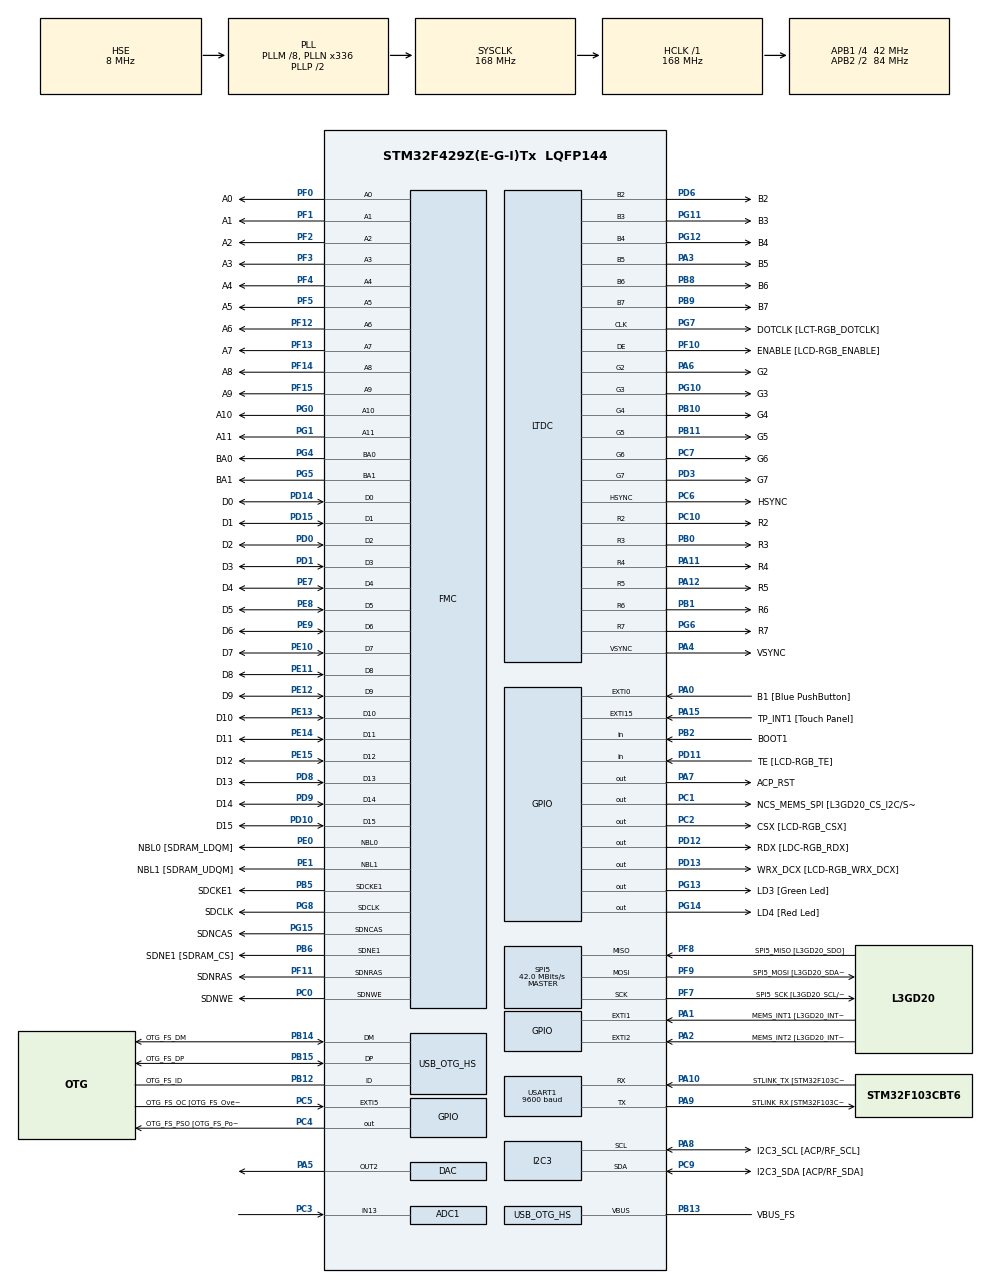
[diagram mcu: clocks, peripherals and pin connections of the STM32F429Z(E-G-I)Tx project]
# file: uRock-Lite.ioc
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ADC1.Channel-17\#ChannelRegularConversion=ADC_CHANNEL_13
ADC1.Channel-18\#ChannelRegularConversion=ADC_CHANNEL_13
ADC1.Channel-19\#ChannelRegularConversion=ADC_CHANNEL_13
ADC1.Channel-20\#ChannelRegularConversion=ADC_CHANNEL_13
ADC1.Channel-21\#ChannelRegularConversion=ADC_CHANNEL_13
ADC1.Channel-22\#ChannelRegularConversion=ADC_CHANNEL_13
ADC1.Channel-23\#ChannelRegularConversion=ADC_CHANNEL_13
ADC1.Channel-7\#ChannelRegularConversion=ADC_CHANNEL_13
ADC1.ClockPrescaler=ADC_CLOCKPRESCALER_PCLK_DIV8
ADC1.ContinuousConvMode=ENABLE
ADC1.DMAContinuousRequests=ENABLE
ADC1.DataAlign=ADC_DATAALIGN_RIGHT
ADC1.DiscontinuousConvMode=DISABLE
ADC1.EOCSelection=EOC_SINGLE_CONV
ADC1.EnableAnalogWatchDog=false
ADC1.ExternalTrigConvEdge=ADC_EXTERNALTRIGCONVEDGE_NONE
ADC1.InjNumberOfConversion=0
ADC1.NbrOfConversion=8
ADC1.NbrOfConversionFlag=1
ADC1.Rank-17\#ChannelRegularConversion=2
ADC1.Rank-18\#ChannelRegularConversion=3
ADC1.Rank-19\#ChannelRegularConversion=4
ADC1.Rank-20\#ChannelRegularConversion=5
ADC1.Rank-21\#ChannelRegularConversion=6
ADC1.Rank-22\#ChannelRegularConversion=7
ADC1.Rank-23\#ChannelRegularConversion=8
ADC1.Rank-7\#ChannelRegularConversion=1
ADC1.Resolution=ADC_RESOLUTION12b
ADC1.SamplingTime-17\#ChannelRegularConversion=ADC_SAMPLETIME_3CYCLES
ADC1.SamplingTime-18\#ChannelRegularConversion=ADC_SAMPLETIME_3CYCLES
ADC1.SamplingTime-19\#ChannelRegularConversion=ADC_SAMPLETIME_3CYCLES
ADC1.SamplingTime-20\#ChannelRegularConversion=ADC_SAMPLETIME_3CYCLES
ADC1.SamplingTime-21\#ChannelRegularConversion=ADC_SAMPLETIME_3CYCLES
ADC1.SamplingTime-22\#ChannelRegularConversion=ADC_SAMPLETIME_3CYCLES
ADC1.SamplingTime-23\#ChannelRegularConversion=ADC_SAMPLETIME_3CYCLES
ADC1.SamplingTime-7\#ChannelRegularConversion=ADC_SAMPLETIME_3CYCLES
ADC1.ScanConvMode=ENABLE
ADC1.master=1
DAC.DAC_Trigger2=DAC_TRIGGER_T6_TRGO
Dma.ADC1.2.Channel=DMA_CHANNEL_0
Dma.ADC1.2.Direction=DMA_PERIPH_TO_MEMORY
Dma.ADC1.2.FIFOMode=DMA_FIFOMODE_DISABLE
Dma.ADC1.2.Instance=DMA2_Stream4
Dma.ADC1.2.MemDataAlignment=DMA_MDATAALIGN_WORD
Dma.ADC1.2.MemInc=DMA_MINC_ENABLE
Dma.ADC1.2.Mode=DMA_CIRCULAR
Dma.ADC1.2.PeriphDataAlignment=DMA_PDATAALIGN_WORD
Dma.ADC1.2.PeriphInc=DMA_PINC_DISABLE
Dma.ADC1.2.Priority=DMA_PRIORITY_MEDIUM
Dma.DAC2.0.Channel=DMA_CHANNEL_7
Dma.DAC2.0.Direction=DMA_MEMORY_TO_PERIPH
Dma.DAC2.0.FIFOMode=DMA_FIFOMODE_DISABLE
Dma.DAC2.0.Instance=DMA1_Stream6
Dma.DAC2.0.MemDataAlignment=DMA_MDATAALIGN_WORD
Dma.DAC2.0.MemInc=DMA_MINC_ENABLE
Dma.DAC2.0.Mode=DMA_CIRCULAR
Dma.DAC2.0.PeriphDataAlignment=DMA_PDATAALIGN_WORD
Dma.DAC2.0.PeriphInc=DMA_PINC_DISABLE
Dma.DAC2.0.Priority=DMA_PRIORITY_VERY_HIGH
Dma.Request0=DAC2
Dma.Request1=TIM6_UP
Dma.Request2=ADC1
Dma.TIM6_UP.1.Channel=DMA_CHANNEL_7
Dma.TIM6_UP.1.Direction=DMA_PERIPH_TO_MEMORY
Dma.TIM6_UP.1.FIFOMode=DMA_FIFOMODE_DISABLE
Dma.TIM6_UP.1.Instance=DMA1_Stream1
Dma.TIM6_UP.1.MemDataAlignment=DMA_MDATAALIGN_HALFWORD
Dma.TIM6_UP.1.MemInc=DMA_MINC_ENABLE
Dma.TIM6_UP.1.Mode=DMA_NORMAL
Dma.TIM6_UP.1.PeriphDataAlignment=DMA_PDATAALIGN_HALFWORD
Dma.TIM6_UP.1.PeriphInc=DMA_PINC_DISABLE
Dma.TIM6_UP.1.Priority=DMA_PRIORITY_LOW
FREERTOS.Tasks01=SignalProcess,3,1024,SignalProcessTask
FREERTOS.configUSE_TIMERS=1
LTDC.Blue=128
LTDC.Blue_L0=128
LTDC.Blue_L1=255
LTDC.Green=128
LTDC.Green_L0=128
LTDC.Green_L1=255
LTDC.ImageHeight_L0=200
LTDC.ImageWidth_L0=200
LTDC.Layers=0
LTDC.Red=128
LTDC.Red_L0=128
LTDC.Red_L1=255
LTDC.WindowX1_L0=0
LTDC.WindowY1_L0=0
Mcu.Family=STM32F4
Mcu.Name=STM32F429Z(E-G-I)Tx
Mcu.Package=LQFP144
NVIC.DMA1_Stream1_IRQn=true\:5\:0\:false
NVIC.DMA1_Stream6_IRQn=true\:5\:0\:false
NVIC.DMA2_Stream4_IRQn=true\:5\:0\:false
NVIC.PriorityGroup=NVIC_PRIORITYGROUP_4
NVIC.USART1_IRQn=true\:5\:0\:false
PA0/WKUP.GPIO_Label=B1 [Blue PushButton]
PA0/WKUP.GPIO_ModeDefaultEXTI=GPIO_MODE_EVT_RISING
PA0/WKUP.GPIO_PuPd=GPIO_NOPULL
PA0/WKUP.Signal=GPXTI0
PA1.GPIO_Label=MEMS_INT1 [L3GD20_INT1]
PA1.GPIO_ModeDefaultEXTI=GPIO_MODE_EVT_RISING
PA1.GPIO_PuPd=GPIO_NOPULL
PA1.Signal=GPXTI1
PA10.GPIO_Label=STLINK_TX [STM32F103CBT6_PA2]
PA10.Mode=Asynchronous
PA10.Signal=USART1_RX
PA11.GPIO_Label=R4
PA11.GPIO_Mode=GPIO_MODE_AF_PP
PA11.GPIO_PuPd=GPIO_NOPULL
PA11.GPIO_Speed=GPIO_SPEED_LOW
PA11.Mode=RGB666
PA11.Signal=LTDC_R4
PA12.GPIO_Label=R5
PA12.GPIO_Mode=GPIO_MODE_AF_PP
PA12.GPIO_PuPd=GPIO_NOPULL
PA12.GPIO_Speed=GPIO_SPEED_LOW
PA12.Mode=RGB666
PA12.Signal=LTDC_R5
PA13.GPIO_Label=SWDIO
PA13.Mode=Serial-Wire
PA13.Signal=SYS_JTMS-SWDIO
PA14.GPIO_Label=SWCLK
PA14.Mode=Serial-Wire
PA14.Signal=SYS_JTCK-SWCLK
PA15.GPIO_Label=TP_INT1 [Touch Panel]
PA15.GPIO_ModeDefaultEXTI=GPIO_MODE_EVT_RISING
PA15.GPIO_PuPd=GPIO_NOPULL
PA15.Signal=GPXTI15
PA2.GPIO_Label=MEMS_INT2 [L3GD20_INT2]
PA2.GPIO_ModeDefaultEXTI=GPIO_MODE_EVT_RISING
PA2.GPIO_PuPd=GPIO_NOPULL
PA2.Signal=GPXTI2
PA3.GPIO_Label=B5
PA3.GPIO_Mode=GPIO_MODE_AF_PP
PA3.GPIO_PuPd=GPIO_NOPULL
PA3.GPIO_Speed=GPIO_SPEED_LOW
PA3.Mode=RGB666
PA3.Signal=LTDC_B5
PA4.GPIO_Label=VSYNC
PA4.GPIO_Mode=GPIO_MODE_AF_PP
PA4.GPIO_PuPd=GPIO_NOPULL
PA4.GPIO_Speed=GPIO_SPEED_LOW
PA4.Mode=RGB666
PA4.Signal=LTDC_VSYNC
PA5.Signal=COMP_DAC2_group
PA6.GPIO_Label=G2
PA6.GPIO_Mode=GPIO_MODE_AF_PP
PA6.GPIO_PuPd=GPIO_NOPULL
PA6.GPIO_Speed=GPIO_SPEED_LOW
PA6.Mode=RGB666
PA6.Signal=LTDC_G2
PA7.GPIO_Label=ACP_RST
PA7.GPIO_Mode=GPIO_MODE_OUTPUT_PP
PA7.GPIO_PuPd=GPIO_NOPULL
PA7.GPIO_Speed=GPIO_SPEED_LOW
PA7.Signal=GPIO_Output
PA8.GPIO_Label=I2C3_SCL [ACP/RF_SCL]
PA8.GPIO_Mode=GPIO_MODE_AF_OD
PA8.GPIO_PuPd=GPIO_NOPULL
PA8.GPIO_Speed=GPIO_SPEED_LOW
PA8.Mode=I2C
PA8.Signal=I2C3_SCL
PA9.GPIO_Label=STLINK_RX [STM32F103CBT6_PA3]
PA9.Mode=Asynchronous
PA9.Signal=USART1_TX
PB0.GPIO_Label=R3
PB0.GPIO_Mode=GPIO_MODE_AF_PP
PB0.GPIO_PuPd=GPIO_NOPULL
PB0.GPIO_Speed=GPIO_SPEED_LOW
PB0.Mode=RGB666
PB0.Signal=LTDC_R3
PB1.GPIO_Label=R6
PB1.GPIO_Mode=GPIO_MODE_AF_PP
PB1.GPIO_PuPd=GPIO_NOPULL
PB1.GPIO_Speed=GPIO_SPEED_LOW
PB1.Mode=RGB666
PB1.Signal=LTDC_R6
PB10.GPIO_Label=G4
PB10.GPIO_Mode=GPIO_MODE_AF_PP
PB10.GPIO_PuPd=GPIO_NOPULL
PB10.GPIO_Speed=GPIO_SPEED_LOW
PB10.Mode=RGB666
PB10.Signal=LTDC_G4
PB11.GPIO_Label=G5
PB11.GPIO_Mode=GPIO_MODE_AF_PP
PB11.GPIO_PuPd=GPIO_NOPULL
PB11.GPIO_Speed=GPIO_SPEED_LOW
PB11.Mode=RGB666
PB11.Signal=LTDC_G5
PB12.GPIO_Label=OTG_FS_ID
PB12.GPIO_Mode=GPIO_MODE_AF_PP
PB12.GPIO_PuPd=GPIO_NOPULL
PB12.GPIO_Speed=GPIO_SPEED_LOW
PB12.Mode=OTG/Dual-Role-Device-FS
PB12.Signal=USB_OTG_HS_ID
PB13.GPIO_Label=VBUS_FS
PB13.GPIO_Mode=GPIO_MODE_INPUT
PB13.GPIO_PuPd=GPIO_NOPULL
PB13.Mode=Activate_VBUS_FS
PB13.Signal=USB_OTG_HS_VBUS
PB14.GPIO_Label=OTG_FS_DM
PB14.GPIO_Mode=GPIO_MODE_AF_PP
PB14.GPIO_PuPd=GPIO_NOPULL
PB14.GPIO_Speed=GPIO_SPEED_LOW
PB14.Mode=OTG/Dual-Role-Device-FS
PB14.Signal=USB_OTG_HS_DM
PB15.GPIO_Label=OTG_FS_DP
PB15.GPIO_Mode=GPIO_MODE_AF_PP
PB15.GPIO_PuPd=GPIO_NOPULL
PB15.GPIO_Speed=GPIO_SPEED_LOW
PB15.Mode=OTG/Dual-Role-Device-FS
PB15.Signal=USB_OTG_HS_DP
PB2/BOOT1.GPIO_Label=BOOT1
PB2/BOOT1.GPIO_Mode=GPIO_MODE_INPUT
PB2/BOOT1.GPIO_PuPd=GPIO_NOPULL
PB2/BOOT1.Signal=GPIO_Input
PB5.GPIO_Label=SDCKE1
PB5.GPIO_Mode=GPIO_MODE_AF_PP
PB5.GPIO_PuPd=GPIO_NOPULL
PB5.GPIO_Speed=GPIO_SPEED_HIGH
PB5.Mode=SdramChipSelect2_1
PB5.Signal=FMC_SDCKE1
PB6.GPIO_Label=SDNE1 [SDRAM_CS]
PB6.GPIO_Mode=GPIO_MODE_AF_PP
PB6.GPIO_PuPd=GPIO_NOPULL
PB6.GPIO_Speed=GPIO_SPEED_HIGH
PB6.Mode=SdramChipSelect2_1
PB6.Signal=FMC_SDNE1
PB8.GPIO_Label=B6
PB8.GPIO_Mode=GPIO_MODE_AF_PP
PB8.GPIO_PuPd=GPIO_NOPULL
PB8.GPIO_Speed=GPIO_SPEED_LOW
PB8.Mode=RGB666
PB8.Signal=LTDC_B6
PB9.GPIO_Label=B7
PB9.GPIO_Mode=GPIO_MODE_AF_PP
PB9.GPIO_PuPd=GPIO_NOPULL
PB9.GPIO_Speed=GPIO_SPEED_LOW
PB9.Mode=RGB666
PB9.Signal=LTDC_B7
PC0.GPIO_Label=SDNWE
PC0.GPIO_Mode=GPIO_MODE_AF_PP
PC0.GPIO_PuPd=GPIO_NOPULL
PC0.GPIO_Speed=GPIO_SPEED_HIGH
PC0.Signal=FMC_SDNWE
PC1.GPIO_Label=NCS_MEMS_SPI [L3GD20_CS_I2C/SPI]
PC1.GPIO_Mode=GPIO_MODE_OUTPUT_PP
PC1.GPIO_PuPd=GPIO_NOPULL
PC1.GPIO_Speed=GPIO_SPEED_LOW
PC1.Signal=GPIO_Output
PC10.GPIO_Label=R2
PC10.GPIO_Mode=GPIO_MODE_AF_PP
PC10.GPIO_PuPd=GPIO_NOPULL
PC10.GPIO_Speed=GPIO_SPEED_LOW
PC10.Mode=RGB666
PC10.Signal=LTDC_R2
PC14/OSC32_IN.GPIO_Label=PC14-OSC32_IN
PC14/OSC32_IN.Signal=RCC_OSC32_IN
PC15/OSC32_OUT.GPIO_Label=PC15-OSC32_OUT
PC15/OSC32_OUT.Signal=RCC_OSC32_OUT
PC2.GPIO_Label=CSX [LCD-RGB_CSX]
PC2.GPIO_Mode=GPIO_MODE_OUTPUT_PP
PC2.GPIO_PuPd=GPIO_NOPULL
PC2.GPIO_Speed=GPIO_SPEED_LOW
PC2.Signal=GPIO_Output
PC3.Signal=ADCx_IN13
PC4.GPIO_Label=OTG_FS_PSO [OTG_FS_PowerSwitchOn]
PC4.GPIO_Mode=GPIO_MODE_OUTPUT_PP
PC4.GPIO_PuPd=GPIO_NOPULL
PC4.GPIO_Speed=GPIO_SPEED_LOW
PC4.Signal=GPIO_Output
PC5.GPIO_Label=OTG_FS_OC [OTG_FS_OverCurrent]
PC5.GPIO_ModeDefaultEXTI=GPIO_MODE_EVT_RISING
PC5.Signal=GPXTI5
PC6.GPIO_Label=HSYNC
PC6.GPIO_Mode=GPIO_MODE_AF_PP
PC6.GPIO_PuPd=GPIO_NOPULL
PC6.GPIO_Speed=GPIO_SPEED_LOW
PC6.Mode=RGB666
PC6.Signal=LTDC_HSYNC
PC7.GPIO_Label=G6
PC7.GPIO_Mode=GPIO_MODE_AF_PP
PC7.GPIO_PuPd=GPIO_NOPULL
PC7.GPIO_Speed=GPIO_SPEED_LOW
PC7.Mode=RGB666
PC7.Signal=LTDC_G6
PC9.GPIO_Label=I2C3_SDA [ACP/RF_SDA]
PC9.GPIO_Mode=GPIO_MODE_AF_OD
PC9.GPIO_PuPd=GPIO_NOPULL
PC9.GPIO_Speed=GPIO_SPEED_LOW
PC9.Mode=I2C
PC9.Signal=I2C3_SDA
PD0.GPIO_Label=D2
PD0.GPIO_Mode=GPIO_MODE_AF_PP
PD0.GPIO_PuPd=GPIO_NOPULL
PD0.GPIO_Speed=GPIO_SPEED_HIGH
PD0.Signal=FMC_D2_DA2
PD1.GPIO_Label=D3
PD1.GPIO_Mode=GPIO_MODE_AF_PP
PD1.GPIO_PuPd=GPIO_NOPULL
PD1.GPIO_Speed=GPIO_SPEED_HIGH
PD1.Signal=FMC_D3_DA3
PD10.GPIO_Label=D15
PD10.GPIO_Mode=GPIO_MODE_AF_PP
PD10.GPIO_PuPd=GPIO_NOPULL
PD10.GPIO_Speed=GPIO_SPEED_HIGH
PD10.Signal=FMC_D15_DA15
PD11.GPIO_Label=TE [LCD-RGB_TE]
PD11.GPIO_Mode=GPIO_MODE_INPUT
PD11.GPIO_PuPd=GPIO_NOPULL
PD11.Signal=GPIO_Input
PD12.GPIO_Label=RDX [LDC-RGB_RDX]
PD12.GPIO_Mode=GPIO_MODE_OUTPUT_PP
PD12.GPIO_PuPd=GPIO_NOPULL
PD12.GPIO_Speed=GPIO_SPEED_LOW
PD12.Signal=GPIO_Output
PD13.GPIO_Label=WRX_DCX [LCD-RGB_WRX_DCX]
PD13.GPIO_Mode=GPIO_MODE_OUTPUT_PP
PD13.GPIO_PuPd=GPIO_NOPULL
PD13.GPIO_Speed=GPIO_SPEED_LOW
PD13.Signal=GPIO_Output
PD14.GPIO_Label=D0
PD14.GPIO_Mode=GPIO_MODE_AF_PP
PD14.GPIO_PuPd=GPIO_NOPULL
PD14.GPIO_Speed=GPIO_SPEED_HIGH
PD14.Signal=FMC_D0_DA0
PD15.GPIO_Label=D1
PD15.GPIO_Mode=GPIO_MODE_AF_PP
PD15.GPIO_PuPd=GPIO_NOPULL
PD15.GPIO_Speed=GPIO_SPEED_HIGH
PD15.Signal=FMC_D1_DA1
PD3.GPIO_Label=G7
PD3.GPIO_Mode=GPIO_MODE_AF_PP
PD3.GPIO_PuPd=GPIO_NOPULL
PD3.GPIO_Speed=GPIO_SPEED_LOW
PD3.Mode=RGB666
PD3.Signal=LTDC_G7
PD6.GPIO_Label=B2
PD6.GPIO_Mode=GPIO_MODE_AF_PP
PD6.GPIO_PuPd=GPIO_NOPULL
PD6.GPIO_Speed=GPIO_SPEED_LOW
PD6.Mode=RGB666
PD6.Signal=LTDC_B2
PD8.GPIO_Label=D13
PD8.GPIO_Mode=GPIO_MODE_AF_PP
PD8.GPIO_PuPd=GPIO_NOPULL
PD8.GPIO_Speed=GPIO_SPEED_HIGH
PD8.Signal=FMC_D13_DA13
PD9.GPIO_Label=D14
PD9.GPIO_Mode=GPIO_MODE_AF_PP
PD9.GPIO_PuPd=GPIO_NOPULL
PD9.GPIO_Speed=GPIO_SPEED_HIGH
PD9.Signal=FMC_D14_DA14
PE0.GPIO_Label=NBL0 [SDRAM_LDQM]
PE0.GPIO_Mode=GPIO_MODE_AF_PP
PE0.GPIO_PuPd=GPIO_NOPULL
PE0.GPIO_Speed=GPIO_SPEED_HIGH
PE0.Signal=FMC_NBL0
PE1.GPIO_Label=NBL1 [SDRAM_UDQM]
PE1.GPIO_Mode=GPIO_MODE_AF_PP
PE1.GPIO_PuPd=GPIO_NOPULL
PE1.GPIO_Speed=GPIO_SPEED_HIGH
PE1.Signal=FMC_NBL1
PE10.GPIO_Label=D7
PE10.GPIO_Mode=GPIO_MODE_AF_PP
PE10.GPIO_PuPd=GPIO_NOPULL
PE10.GPIO_Speed=GPIO_SPEED_HIGH
PE10.Signal=FMC_D7_DA7
PE11.GPIO_Label=D8
PE11.GPIO_Mode=GPIO_MODE_AF_PP
PE11.GPIO_PuPd=GPIO_NOPULL
PE11.GPIO_Speed=GPIO_SPEED_HIGH
PE11.Signal=FMC_D8_DA8
PE12.GPIO_Label=D9
PE12.GPIO_Mode=GPIO_MODE_AF_PP
PE12.GPIO_PuPd=GPIO_NOPULL
PE12.GPIO_Speed=GPIO_SPEED_HIGH
PE12.Signal=FMC_D9_DA9
PE13.GPIO_Label=D10
PE13.GPIO_Mode=GPIO_MODE_AF_PP
PE13.GPIO_PuPd=GPIO_NOPULL
PE13.GPIO_Speed=GPIO_SPEED_HIGH
PE13.Signal=FMC_D10_DA10
PE14.GPIO_Label=D11
PE14.GPIO_Mode=GPIO_MODE_AF_PP
PE14.GPIO_PuPd=GPIO_NOPULL
PE14.GPIO_Speed=GPIO_SPEED_HIGH
PE14.Signal=FMC_D11_DA11
PE15.GPIO_Label=D12
PE15.GPIO_Mode=GPIO_MODE_AF_PP
PE15.GPIO_PuPd=GPIO_NOPULL
PE15.GPIO_Speed=GPIO_SPEED_HIGH
PE15.Signal=FMC_D12_DA12
PE7.GPIO_Label=D4
PE7.GPIO_Mode=GPIO_MODE_AF_PP
PE7.GPIO_PuPd=GPIO_NOPULL
PE7.GPIO_Speed=GPIO_SPEED_HIGH
PE7.Signal=FMC_D4_DA4
PE8.GPIO_Label=D5
PE8.GPIO_Mode=GPIO_MODE_AF_PP
PE8.GPIO_PuPd=GPIO_NOPULL
PE8.GPIO_Speed=GPIO_SPEED_HIGH
PE8.Signal=FMC_D5_DA5
PE9.GPIO_Label=D6
PE9.GPIO_Mode=GPIO_MODE_AF_PP
PE9.GPIO_PuPd=GPIO_NOPULL
PE9.GPIO_Speed=GPIO_SPEED_HIGH
PE9.Signal=FMC_D6_DA6
PF0.GPIO_Label=A0
PF0.GPIO_Mode=GPIO_MODE_AF_PP
PF0.GPIO_PuPd=GPIO_NOPULL
PF0.GPIO_Speed=GPIO_SPEED_HIGH
PF0.Signal=FMC_A0
PF1.GPIO_Label=A1
PF1.GPIO_Mode=GPIO_MODE_AF_PP
PF1.GPIO_PuPd=GPIO_NOPULL
PF1.GPIO_Speed=GPIO_SPEED_HIGH
PF1.Signal=FMC_A1
PF10.GPIO_Label=ENABLE [LCD-RGB_ENABLE]
PF10.GPIO_Mode=GPIO_MODE_AF_PP
PF10.GPIO_PuPd=GPIO_NOPULL
PF10.GPIO_Speed=GPIO_SPEED_LOW
PF10.Mode=RGB666
PF10.Signal=LTDC_DE
PF11.GPIO_Label=SDNRAS
PF11.GPIO_Mode=GPIO_MODE_AF_PP
PF11.GPIO_PuPd=GPIO_NOPULL
PF11.GPIO_Speed=GPIO_SPEED_HIGH
PF11.Signal=FMC_SDNRAS
PF12.GPIO_Label=A6
PF12.GPIO_Mode=GPIO_MODE_AF_PP
PF12.GPIO_PuPd=GPIO_NOPULL
PF12.GPIO_Speed=GPIO_SPEED_HIGH
PF12.Signal=FMC_A6
PF13.GPIO_Label=A7
PF13.GPIO_Mode=GPIO_MODE_AF_PP
PF13.GPIO_PuPd=GPIO_NOPULL
PF13.GPIO_Speed=GPIO_SPEED_HIGH
PF13.Signal=FMC_A7
PF14.GPIO_Label=A8
PF14.GPIO_Mode=GPIO_MODE_AF_PP
PF14.GPIO_PuPd=GPIO_NOPULL
PF14.GPIO_Speed=GPIO_SPEED_HIGH
PF14.Signal=FMC_A8
PF15.GPIO_Label=A9
PF15.GPIO_Mode=GPIO_MODE_AF_PP
PF15.GPIO_PuPd=GPIO_NOPULL
PF15.GPIO_Speed=GPIO_SPEED_HIGH
PF15.Signal=FMC_A9
PF2.GPIO_Label=A2
PF2.GPIO_Mode=GPIO_MODE_AF_PP
PF2.GPIO_PuPd=GPIO_NOPULL
PF2.GPIO_Speed=GPIO_SPEED_HIGH
PF2.Signal=FMC_A2
PF3.GPIO_Label=A3
PF3.GPIO_Mode=GPIO_MODE_AF_PP
PF3.GPIO_PuPd=GPIO_NOPULL
PF3.GPIO_Speed=GPIO_SPEED_HIGH
PF3.Signal=FMC_A3
PF4.GPIO_Label=A4
PF4.GPIO_Mode=GPIO_MODE_AF_PP
PF4.GPIO_PuPd=GPIO_NOPULL
PF4.GPIO_Speed=GPIO_SPEED_HIGH
PF4.Signal=FMC_A4
PF5.GPIO_Label=A5
PF5.GPIO_Mode=GPIO_MODE_AF_PP
PF5.GPIO_PuPd=GPIO_NOPULL
PF5.GPIO_Speed=GPIO_SPEED_HIGH
PF5.Signal=FMC_A5
PF7.GPIO_Label=SPI5_SCK [L3GD20_SCL/SPC]
PF7.GPIO_Mode=GPIO_MODE_AF_PP
PF7.GPIO_PuPd=GPIO_NOPULL
PF7.GPIO_Speed=GPIO_SPEED_LOW
PF7.Mode=Full_Duplex_Master
PF7.Signal=SPI5_SCK
PF8.GPIO_Label=SPI5_MISO [L3GD20_SDO]
PF8.GPIO_Mode=GPIO_MODE_AF_PP
PF8.GPIO_PuPd=GPIO_NOPULL
PF8.GPIO_Speed=GPIO_SPEED_LOW
PF8.Mode=Full_Duplex_Master
PF8.Signal=SPI5_MISO
PF9.GPIO_Label=SPI5_MOSI [L3GD20_SDA/SDI/SDO]
PF9.GPIO_Mode=GPIO_MODE_AF_PP
PF9.GPIO_PuPd=GPIO_NOPULL
PF9.GPIO_Speed=GPIO_SPEED_LOW
PF9.Mode=Full_Duplex_Master
PF9.Signal=SPI5_MOSI
PG0.GPIO_Label=A10
PG0.GPIO_Mode=GPIO_MODE_AF_PP
PG0.GPIO_PuPd=GPIO_NOPULL
PG0.GPIO_Speed=GPIO_SPEED_HIGH
PG0.Signal=FMC_A10
PG1.GPIO_Label=A11
PG1.GPIO_Mode=GPIO_MODE_AF_PP
PG1.GPIO_PuPd=GPIO_NOPULL
PG1.GPIO_Speed=GPIO_SPEED_HIGH
PG1.Signal=FMC_A11
PG10.GPIO_Label=G3
PG10.GPIO_Mode=GPIO_MODE_AF_PP
PG10.GPIO_PuPd=GPIO_NOPULL
PG10.GPIO_Speed=GPIO_SPEED_LOW
PG10.Mode=RGB666
PG10.Signal=LTDC_G3
PG11.GPIO_Label=B3
PG11.GPIO_Mode=GPIO_MODE_AF_PP
PG11.GPIO_PuPd=GPIO_NOPULL
PG11.GPIO_Speed=GPIO_SPEED_LOW
PG11.Mode=RGB666
PG11.Signal=LTDC_B3
PG12.GPIO_Label=B4
PG12.GPIO_Mode=GPIO_MODE_AF_PP
PG12.GPIO_PuPd=GPIO_NOPULL
PG12.GPIO_Speed=GPIO_SPEED_LOW
PG12.Mode=RGB666
PG12.Signal=LTDC_B4
PG13.GPIO_Label=LD3 [Green Led]
PG13.GPIO_Mode=GPIO_MODE_OUTPUT_PP
PG13.GPIO_PuPd=GPIO_NOPULL
PG13.GPIO_Speed=GPIO_SPEED_LOW
PG13.Signal=GPIO_Output
PG14.GPIO_Label=LD4 [Red Led]
PG14.GPIO_Mode=GPIO_MODE_OUTPUT_PP
PG14.GPIO_PuPd=GPIO_NOPULL
PG14.GPIO_Speed=GPIO_SPEED_LOW
PG14.Signal=GPIO_Output
PG15.GPIO_Label=SDNCAS
PG15.GPIO_Mode=GPIO_MODE_AF_PP
PG15.GPIO_PuPd=GPIO_NOPULL
PG15.GPIO_Speed=GPIO_SPEED_HIGH
PG15.Signal=FMC_SDNCAS
PG4.GPIO_Label=BA0
PG4.GPIO_Mode=GPIO_MODE_AF_PP
PG4.GPIO_PuPd=GPIO_NOPULL
PG4.GPIO_Speed=GPIO_SPEED_HIGH
PG4.Signal=FMC_A14_BA0
PG5.GPIO_Label=BA1
PG5.GPIO_Mode=GPIO_MODE_AF_PP
PG5.GPIO_PuPd=GPIO_NOPULL
PG5.GPIO_Speed=GPIO_SPEED_HIGH
PG5.Signal=FMC_A15_BA1
PG6.GPIO_Label=R7
PG6.GPIO_Mode=GPIO_MODE_AF_PP
PG6.GPIO_PuPd=GPIO_NOPULL
PG6.GPIO_Speed=GPIO_SPEED_LOW
PG6.Mode=RGB666
PG6.Signal=LTDC_R7
PG7.GPIO_Label=DOTCLK [LCT-RGB_DOTCLK]
PG7.GPIO_Mode=GPIO_MODE_AF_PP
PG7.GPIO_PuPd=GPIO_NOPULL
PG7.GPIO_Speed=GPIO_SPEED_LOW
PG7.Mode=RGB666
PG7.Signal=LTDC_CLK
PG8.GPIO_Label=SDCLK
PG8.GPIO_Mode=GPIO_MODE_AF_PP
PG8.GPIO_PuPd=GPIO_NOPULL
PG8.GPIO_Speed=GPIO_SPEED_HIGH
PG8.Signal=FMC_SDCLK
PH0/OSC_IN.GPIO_Label=PH0-OSC_IN
PH0/OSC_IN.Mode=HSE-External-Oscillator
PH0/OSC_IN.Signal=RCC_OSC_IN
PH1/OSC_OUT.GPIO_Label=PH1-OSC_OUT
PH1/OSC_OUT.Mode=HSE-External-Oscillator
PH1/OSC_OUT.Signal=RCC_OSC_OUT
ProjectManager.TargetToolchain=SW4STM32
RCC.48MHZClocksFreq_Value=48000000
RCC.AHBFreq_Value=168000000
RCC.APB1CLKDivider=RCC_HCLK_DIV4
RCC.APB1Freq_Value=42000000
RCC.APB1TimFreq_Value=84000000
RCC.APB2CLKDivider=RCC_HCLK_DIV2
RCC.APB2Freq_Value=84000000
RCC.APB2TimFreq_Value=168000000
RCC.CortexFreq_Value=168000000
RCC.HCLKFreq_Value=168000000
RCC.HSE_VALUE=8000000
RCC.HSI_VALUE=16000000
RCC.LSE_VALUE=32768
RCC.PLLM=8
RCC.PLLN=336
RCC.PLLQ=7
RCC.PLLSAIN=260
RCC.SYSCLKFreq_VALUE=168000000
RCC.SYSCLKSource=RCC_SYSCLKSOURCE_PLLCLK
RCC.VCOOutputFreq_Value=336000000
SH.ADCx_IN13.0=ADC1_IN13,IN13
SH.COMP_DAC2_group.0=DAC_OUT2,DAC_OUT2
SH.FMC_A0.0=FMC_A0,12b-sda1
SH.FMC_A1.0=FMC_A1,12b-sda1
SH.FMC_A10.0=FMC_A10,12b-sda1
SH.FMC_A11.0=FMC_A11,12b-sda1
SH.FMC_A14_BA0.0=FMC_BA0,FourSdramBanks1
SH.FMC_A15_BA1.0=FMC_BA1,FourSdramBanks1
SH.FMC_A2.0=FMC_A2,12b-sda1
SH.FMC_A3.0=FMC_A3,12b-sda1
SH.FMC_A4.0=FMC_A4,12b-sda1
SH.FMC_A5.0=FMC_A5,12b-sda1
SH.FMC_A6.0=FMC_A6,12b-sda1
SH.FMC_A7.0=FMC_A7,12b-sda1
SH.FMC_A8.0=FMC_A8,12b-sda1
SH.FMC_A9.0=FMC_A9,12b-sda1
SH.FMC_D0_DA0.0=FMC_D0,sd-16b-d1
SH.FMC_D10_DA10.0=FMC_D10,sd-16b-d1
SH.FMC_D11_DA11.0=FMC_D11,sd-16b-d1
SH.FMC_D12_DA12.0=FMC_D12,sd-16b-d1
SH.FMC_D13_DA13.0=FMC_D13,sd-16b-d1
SH.FMC_D14_DA14.0=FMC_D14,sd-16b-d1
SH.FMC_D15_DA15.0=FMC_D15,sd-16b-d1
SH.FMC_D1_DA1.0=FMC_D1,sd-16b-d1
SH.FMC_D2_DA2.0=FMC_D2,sd-16b-d1
SH.FMC_D3_DA3.0=FMC_D3,sd-16b-d1
SH.FMC_D4_DA4.0=FMC_D4,sd-16b-d1
SH.FMC_D5_DA5.0=FMC_D5,sd-16b-d1
SH.FMC_D6_DA6.0=FMC_D6,sd-16b-d1
SH.FMC_D7_DA7.0=FMC_D7,sd-16b-d1
SH.FMC_D8_DA8.0=FMC_D8,sd-16b-d1
SH.FMC_D9_DA9.0=FMC_D9,sd-16b-d1
SH.FMC_NBL0.0=FMC_NBL0,Sd2ByteEnable1
SH.FMC_NBL1.0=FMC_NBL1,Sd2ByteEnable1
SH.FMC_SDCLK.0=FMC_SDCLK,12b-sda1
SH.FMC_SDNCAS.0=FMC_SDNCAS,12b-sda1
SH.FMC_SDNRAS.0=FMC_SDNRAS,12b-sda1
SH.FMC_SDNWE.0=FMC_SDNWE,12b-sda1
SPI5.CalculateBaudRate=42.0 MBits/s
SPI5.Mode=SPI_MODE_MASTER
TIM6.Period=0x0ED
TIM6.TIM_MasterOutputTrigger=TIM_TRGO_UPDATE
USART1.BaudRate=9600
VP_FREERTOS_VS_ENABLE.Mode=Enabled
VP_TIM6_VS_ClockSourceINT.Mode=Enable_Timer
board=STM32F429I-DISC1

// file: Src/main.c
/**
  ******************************************************************************
  * File Name          : main.c
  * Description        : Main program body
  ******************************************************************************
  *
  * COPYRIGHT(c) 2016 STMicroelectronics
  *
  * Redistribution and use in source and binary forms, with or without modification,
  * are permitted provided that the following conditions are met:
  *   1. Redistributions of source code must retain the above copyright notice,
  *      this list of conditions and the following disclaimer.
  *   2. Redistributions in binary form must reproduce the above copyright notice,
  *      this list of conditions and the following disclaimer in the documentation
  *      and/or other materials provided with the distribution.
  *   3. Neither the name of STMicroelectronics nor the names of its contributors
  *      may be used to endorse or promote products derived from this software
  *      without specific prior written permission.
  *
  * THIS SOFTWARE IS PROVIDED BY THE COPYRIGHT HOLDERS AND CONTRIBUTORS "AS IS"
  * AND ANY EXPRESS OR IMPLIED WARRANTIES, INCLUDING, BUT NOT LIMITED TO, THE
  * IMPLIED WARRANTIES OF MERCHANTABILITY AND FITNESS FOR A PARTICULAR PURPOSE ARE
  * DISCLAIMED. IN NO EVENT SHALL THE COPYRIGHT HOLDER OR CONTRIBUTORS BE LIABLE
  * FOR ANY DIRECT, INDIRECT, INCIDENTAL, SPECIAL, EXEMPLARY, OR CONSEQUENTIAL
  * DAMAGES (INCLUDING, BUT NOT LIMITED TO, PROCUREMENT OF SUBSTITUTE GOODS OR
  * SERVICES; LOSS OF USE, DATA, OR PROFITS; OR BUSINESS INTERRUPTION) HOWEVER
  * CAUSED AND ON ANY THEORY OF LIABILITY, WHETHER IN CONTRACT, STRICT LIABILITY,
  * OR TORT (INCLUDING NEGLIGENCE OR OTHERWISE) ARISING IN ANY WAY OUT OF THE USE
  * OF THIS SOFTWARE, EVEN IF ADVISED OF THE POSSIBILITY OF SUCH DAMAGE.
  *
  ******************************************************************************
  */
#include "stm32f4xx_hal.h"
#include "cmsis_os.h"

/* USER CODE BEGIN Includes */
#include "param.h"
#include "effect.h"
#include "dsp.h"
#include "bluetooth_handler.h"
/* USER CODE END Includes */

ADC_HandleTypeDef hadc1;
DMA_HandleTypeDef hdma_adc1;

DAC_HandleTypeDef hdac;
DMA_HandleTypeDef hdma_dac2;

I2C_HandleTypeDef hi2c3;

LTDC_HandleTypeDef hltdc;

SPI_HandleTypeDef hspi5;

TIM_HandleTypeDef htim6;
DMA_HandleTypeDef hdma_tim6_up;

UART_HandleTypeDef huart1;

SDRAM_HandleTypeDef hsdram1;
osThreadId SignalProcessHandle;

/* USER CODE BEGIN PV */
/* Private variables ---------------------------------------------------------*/

/* USER CODE END PV */

void SystemClock_Config(void);
static void MX_GPIO_Init(void);
static void MX_DMA_Init(void);
static void MX_ADC1_Init(void);
static void MX_DAC_Init(void);
static void MX_FMC_Init(void);
static void MX_I2C3_Init(void);
static void MX_LTDC_Init(void);
static void MX_SPI5_Init(void);
static void MX_TIM6_Init(void);
static void MX_USART1_UART_Init(void);
static void MX_USB_OTG_HS_USB_Init(void);
void SignalProcessTask(void const * argument);

/* USER CODE BEGIN PFP */
/* Private function prototypes -----------------------------------------------*/

/* USER CODE END PFP */

int main(void)
{

  /* MCU Configuration----------------------------------------------------------*/

  /* Reset of all peripherals, Initializes the Flash interface and the Systick. */
  HAL_Init();

  /* Configure the system clock */
  SystemClock_Config();

  /* Initialize all configured peripherals */
  MX_GPIO_Init();
  MX_DMA_Init();
  MX_ADC1_Init();
  MX_DAC_Init();
  MX_FMC_Init();
  MX_I2C3_Init();
  MX_LTDC_Init();
  MX_SPI5_Init();
  MX_TIM6_Init();
  MX_USART1_UART_Init();
  MX_USB_OTG_HS_USB_Init();

  /* Create the thread(s) */
  /* definition and creation of SignalProcess */
  osThreadDef(SignalProcess, SignalProcessTask, osPriorityRealtime, 0, 1024);
  SignalProcessHandle = osThreadCreate(osThread(SignalProcess), NULL);

  /* Start scheduler */
  osKernelStart();

  /* We should never get here as control is now taken by the scheduler */

  /* Infinite loop */
  while (1)
  {

  }

}

/** System Clock Configuration
*/
void SystemClock_Config(void)
{

  RCC_OscInitTypeDef RCC_OscInitStruct;
  RCC_ClkInitTypeDef RCC_ClkInitStruct;
  RCC_PeriphCLKInitTypeDef PeriphClkInitStruct;

  __PWR_CLK_ENABLE();

  __HAL_PWR_VOLTAGESCALING_CONFIG(PWR_REGULATOR_VOLTAGE_SCALE1);

  RCC_OscInitStruct.OscillatorType = RCC_OSCILLATORTYPE_HSE;
  RCC_OscInitStruct.HSEState = RCC_HSE_ON;
  RCC_OscInitStruct.PLL.PLLState = RCC_PLL_ON;
  RCC_OscInitStruct.PLL.PLLSource = RCC_PLLSOURCE_HSE;
  RCC_OscInitStruct.PLL.PLLM = 8;
  RCC_OscInitStruct.PLL.PLLN = 336;
  RCC_OscInitStruct.PLL.PLLP = RCC_PLLP_DIV2;
  RCC_OscInitStruct.PLL.PLLQ = 7;
  HAL_RCC_OscConfig(&RCC_OscInitStruct);

  RCC_ClkInitStruct.ClockType = RCC_CLOCKTYPE_SYSCLK|RCC_CLOCKTYPE_PCLK1
                              |RCC_CLOCKTYPE_PCLK2;
  RCC_ClkInitStruct.SYSCLKSource = RCC_SYSCLKSOURCE_PLLCLK;
  RCC_ClkInitStruct.AHBCLKDivider = RCC_SYSCLK_DIV1;
  RCC_ClkInitStruct.APB1CLKDivider = RCC_HCLK_DIV4;
  RCC_ClkInitStruct.APB2CLKDivider = RCC_HCLK_DIV2;
  HAL_RCC_ClockConfig(&RCC_ClkInitStruct, FLASH_LATENCY_5);

  PeriphClkInitStruct.PeriphClockSelection = RCC_PERIPHCLK_LTDC;
  PeriphClkInitStruct.PLLSAI.PLLSAIN = 260;
  PeriphClkInitStruct.PLLSAI.PLLSAIR = 2;
  PeriphClkInitStruct.PLLSAIDivR = RCC_PLLSAIDIVR_2;
  HAL_RCCEx_PeriphCLKConfig(&PeriphClkInitStruct);

  HAL_SYSTICK_Config(HAL_RCC_GetHCLKFreq()/1000);

  HAL_SYSTICK_CLKSourceConfig(SYSTICK_CLKSOURCE_HCLK);

  /* SysTick_IRQn interrupt configuration */
  HAL_NVIC_SetPriority(SysTick_IRQn, 15, 0);
}

/* ADC1 init function */
void MX_ADC1_Init(void)
{

  ADC_ChannelConfTypeDef sConfig;

    /**Configure the global features of the ADC (Clock, Resolution, Data Alignment and number of conversion)
    */
  hadc1.Instance = ADC1;
  hadc1.Init.ClockPrescaler = ADC_CLOCKPRESCALER_PCLK_DIV8;
  hadc1.Init.Resolution = ADC_RESOLUTION12b;
  hadc1.Init.ScanConvMode = ENABLE;
  hadc1.Init.ContinuousConvMode = ENABLE;
  hadc1.Init.DiscontinuousConvMode = DISABLE;
  hadc1.Init.ExternalTrigConvEdge = ADC_EXTERNALTRIGCONVEDGE_NONE;
  hadc1.Init.DataAlign = ADC_DATAALIGN_RIGHT;
  hadc1.Init.NbrOfConversion = 8;
  hadc1.Init.DMAContinuousRequests = ENABLE;
  hadc1.Init.EOCSelection = EOC_SINGLE_CONV;
  HAL_ADC_Init(&hadc1);

    /**Configure for the selected ADC regular channel its corresponding rank in the sequencer and its sample time.
    */
  sConfig.Channel = ADC_CHANNEL_13;
  sConfig.Rank = 1;
  sConfig.SamplingTime = ADC_SAMPLETIME_3CYCLES;
  HAL_ADC_ConfigChannel(&hadc1, &sConfig);

    /**Configure for the selected ADC regular channel its corresponding rank in the sequencer and its sample time.
    */
  sConfig.Rank = 2;
  HAL_ADC_ConfigChannel(&hadc1, &sConfig);

    /**Configure for the selected ADC regular channel its corresponding rank in the sequencer and its sample time.
    */
  sConfig.Rank = 3;
  HAL_ADC_ConfigChannel(&hadc1, &sConfig);

    /**Configure for the selected ADC regular channel its corresponding rank in the sequencer and its sample time.
    */
  sConfig.Rank = 4;
  HAL_ADC_ConfigChannel(&hadc1, &sConfig);

    /**Configure for the selected ADC regular channel its corresponding rank in the sequencer and its sample time.
    */
  sConfig.Rank = 5;
  HAL_ADC_ConfigChannel(&hadc1, &sConfig);

    /**Configure for the selected ADC regular channel its corresponding rank in the sequencer and its sample time.
    */
  sConfig.Rank = 6;
  HAL_ADC_ConfigChannel(&hadc1, &sConfig);

    /**Configure for the selected ADC regular channel its corresponding rank in the sequencer and its sample time.
    */
  sConfig.Rank = 7;
  HAL_ADC_ConfigChannel(&hadc1, &sConfig);

    /**Configure for the selected ADC regular channel its corresponding rank in the sequencer and its sample time.
    */
  sConfig.Rank = 8;
  HAL_ADC_ConfigChannel(&hadc1, &sConfig);

}

/* DAC init function */
void MX_DAC_Init(void)
{

  DAC_ChannelConfTypeDef sConfig;

    /**DAC Initialization
    */
  hdac.Instance = DAC;
  HAL_DAC_Init(&hdac);

    /**DAC channel OUT2 config
    */
  sConfig.DAC_Trigger = DAC_TRIGGER_T6_TRGO;
  sConfig.DAC_OutputBuffer = DAC_OUTPUTBUFFER_ENABLE;
  HAL_DAC_ConfigChannel(&hdac, &sConfig, DAC_CHANNEL_2);

}

/* I2C3 init function */
void MX_I2C3_Init(void)
{

  hi2c3.Instance = I2C3;
  hi2c3.Init.ClockSpeed = 100000;
  hi2c3.Init.DutyCycle = I2C_DUTYCYCLE_2;
  hi2c3.Init.OwnAddress1 = 0;
  hi2c3.Init.AddressingMode = I2C_ADDRESSINGMODE_7BIT;
  hi2c3.Init.DualAddressMode = I2C_DUALADDRESS_DISABLED;
  hi2c3.Init.OwnAddress2 = 0;
  hi2c3.Init.GeneralCallMode = I2C_GENERALCALL_DISABLED;
  hi2c3.Init.NoStretchMode = I2C_NOSTRETCH_DISABLED;
  HAL_I2C_Init(&hi2c3);

}

/* LTDC init function */
void MX_LTDC_Init(void)
{

  LTDC_LayerCfgTypeDef pLayerCfg;

  hltdc.Instance = LTDC;
  hltdc.Init.HSPolarity = LTDC_HSPOLARITY_AL;
  hltdc.Init.VSPolarity = LTDC_VSPOLARITY_AL;
  hltdc.Init.DEPolarity = LTDC_DEPOLARITY_AL;
  hltdc.Init.PCPolarity = LTDC_PCPOLARITY_IPC;
  hltdc.Init.HorizontalSync = 7;
  hltdc.Init.VerticalSync = 3;
  hltdc.Init.AccumulatedHBP = 14;
  hltdc.Init.AccumulatedVBP = 5;
  hltdc.Init.AccumulatedActiveW = 654;
  hltdc.Init.AccumulatedActiveH = 485;
  hltdc.Init.TotalWidth = 660;
  hltdc.Init.TotalHeigh = 487;
  hltdc.Init.Backcolor.Blue = 128;
  hltdc.Init.Backcolor.Green = 128;
  hltdc.Init.Backcolor.Red = 128;
  HAL_LTDC_Init(&hltdc);

  pLayerCfg.WindowX0 = 0;
  pLayerCfg.WindowX1 = 0;
  pLayerCfg.WindowY0 = 0;
  pLayerCfg.WindowY1 = 0;
  pLayerCfg.PixelFormat = LTDC_PIXEL_FORMAT_ARGB8888;
  pLayerCfg.Alpha = 0;
  pLayerCfg.Alpha0 = 0;
  pLayerCfg.BlendingFactor1 = LTDC_BLENDING_FACTOR1_CA;
  pLayerCfg.BlendingFactor2 = LTDC_BLENDING_FACTOR2_CA;
  pLayerCfg.FBStartAdress = 0;
  pLayerCfg.ImageWidth = 200;
  pLayerCfg.ImageHeight = 200;
  pLayerCfg.Backcolor.Blue = 128;
  pLayerCfg.Backcolor.Green = 128;
  pLayerCfg.Backcolor.Red = 128;
  HAL_LTDC_ConfigLayer(&hltdc, &pLayerCfg, 0);

}

/* SPI5 init function */
void MX_SPI5_Init(void)
{

  hspi5.Instance = SPI5;
  hspi5.Init.Mode = SPI_MODE_MASTER;
  hspi5.Init.Direction = SPI_DIRECTION_2LINES;
  hspi5.Init.DataSize = SPI_DATASIZE_8BIT;
  hspi5.Init.CLKPolarity = SPI_POLARITY_LOW;
  hspi5.Init.CLKPhase = SPI_PHASE_1EDGE;
  hspi5.Init.NSS = SPI_NSS_SOFT;
  hspi5.Init.BaudRatePrescaler = SPI_BAUDRATEPRESCALER_2;
  hspi5.Init.FirstBit = SPI_FIRSTBIT_MSB;
  hspi5.Init.TIMode = SPI_TIMODE_DISABLED;
  hspi5.Init.CRCCalculation = SPI_CRCCALCULATION_DISABLED;
  hspi5.Init.CRCPolynomial = 10;
  HAL_SPI_Init(&hspi5);

}

/* TIM6 init function */
void MX_TIM6_Init(void)
{

  TIM_MasterConfigTypeDef sMasterConfig;

  htim6.Instance = TIM6;
  htim6.Init.Prescaler = 0;
  htim6.Init.CounterMode = TIM_COUNTERMODE_UP;
  htim6.Init.Period = 0x0ED;
  HAL_TIM_Base_Init(&htim6);

  sMasterConfig.MasterOutputTrigger = TIM_TRGO_UPDATE;
  sMasterConfig.MasterSlaveMode = TIM_MASTERSLAVEMODE_DISABLE;
  HAL_TIMEx_MasterConfigSynchronization(&htim6, &sMasterConfig);

}

/* USART1 init function */
void MX_USART1_UART_Init(void)
{

  huart1.Instance = USART1;
  huart1.Init.BaudRate = 9600;
  huart1.Init.WordLength = UART_WORDLENGTH_8B;
  huart1.Init.StopBits = UART_STOPBITS_1;
  huart1.Init.Parity = UART_PARITY_NONE;
  huart1.Init.Mode = UART_MODE_TX_RX;
  huart1.Init.HwFlowCtl = UART_HWCONTROL_NONE;
  huart1.Init.OverSampling = UART_OVERSAMPLING_16;
  HAL_UART_Init(&huart1);

}

/* USB_OTG_HS init function */
void MX_USB_OTG_HS_USB_Init(void)
{

}

void MX_DMA_Init(void)
{
  /* DMA controller clock enable */
  __DMA1_CLK_ENABLE();
  __DMA2_CLK_ENABLE();

  /* DMA interrupt init */
  HAL_NVIC_SetPriority(DMA1_Stream1_IRQn, 5, 0);
  HAL_NVIC_EnableIRQ(DMA1_Stream1_IRQn);
  HAL_NVIC_SetPriority(DMA1_Stream6_IRQn, 5, 0);
  HAL_NVIC_EnableIRQ(DMA1_Stream6_IRQn);
  HAL_NVIC_SetPriority(DMA2_Stream4_IRQn, 5, 0);
  HAL_NVIC_EnableIRQ(DMA2_Stream4_IRQn);

}
/* FMC initialization function */
void MX_FMC_Init(void)
{
  FMC_SDRAM_TimingTypeDef SdramTiming;

  /** Perform the SDRAM1 memory initialization sequence
  */
  hsdram1.Instance = FMC_SDRAM_DEVICE;
  /* hsdram1.Init */
  hsdram1.Init.SDBank = FMC_SDRAM_BANK2;
  hsdram1.Init.ColumnBitsNumber = FMC_SDRAM_COLUMN_BITS_NUM_8;
  hsdram1.Init.RowBitsNumber = FMC_SDRAM_ROW_BITS_NUM_11;
  hsdram1.Init.MemoryDataWidth = FMC_SDRAM_MEM_BUS_WIDTH_16;
  hsdram1.Init.InternalBankNumber = FMC_SDRAM_INTERN_BANKS_NUM_4;
  hsdram1.Init.CASLatency = FMC_SDRAM_CAS_LATENCY_1;
  hsdram1.Init.WriteProtection = FMC_SDRAM_WRITE_PROTECTION_DISABLE;
  hsdram1.Init.SDClockPeriod = FMC_SDRAM_CLOCK_DISABLE;
  hsdram1.Init.ReadBurst = FMC_SDRAM_RBURST_DISABLE;
  hsdram1.Init.ReadPipeDelay = FMC_SDRAM_RPIPE_DELAY_0;
  /* SdramTiming */
  SdramTiming.LoadToActiveDelay = 16;
  SdramTiming.ExitSelfRefreshDelay = 16;
  SdramTiming.SelfRefreshTime = 16;
  SdramTiming.RowCycleDelay = 16;
  SdramTiming.WriteRecoveryTime = 16;
  SdramTiming.RPDelay = 16;
  SdramTiming.RCDDelay = 16;

  HAL_SDRAM_Init(&hsdram1, &SdramTiming);

}

/** Configure pins as
        * Analog
        * Input
        * Output
        * EVENT_OUT
        * EXTI
     PB12   ------> USB_OTG_HS_ID
     PB13   ------> USB_OTG_HS_VBUS
     PB14   ------> USB_OTG_HS_DM
     PB15   ------> USB_OTG_HS_DP
*/
void MX_GPIO_Init(void)
{

  GPIO_InitTypeDef GPIO_InitStruct;

  /* GPIO Ports Clock Enable */
  __GPIOC_CLK_ENABLE();
  __GPIOF_CLK_ENABLE();
  __GPIOH_CLK_ENABLE();
  __GPIOA_CLK_ENABLE();
  __GPIOB_CLK_ENABLE();
  __GPIOG_CLK_ENABLE();
  __GPIOE_CLK_ENABLE();
  __GPIOD_CLK_ENABLE();

  /*Configure GPIO pins : NCS_MEMS_SPI_Pin CSX_Pin OTG_FS_PSO_Pin */
  GPIO_InitStruct.Pin = NCS_MEMS_SPI_Pin|CSX_Pin|OTG_FS_PSO_Pin;
  GPIO_InitStruct.Mode = GPIO_MODE_OUTPUT_PP;
  GPIO_InitStruct.Pull = GPIO_NOPULL;
  GPIO_InitStruct.Speed = GPIO_SPEED_LOW;
  HAL_GPIO_Init(GPIOC, &GPIO_InitStruct);

  /*Configure GPIO pins : B1_Pin MEMS_INT1_Pin MEMS_INT2_Pin TP_INT1_Pin */
  GPIO_InitStruct.Pin = B1_Pin|MEMS_INT1_Pin|MEMS_INT2_Pin|TP_INT1_Pin;
  GPIO_InitStruct.Mode = GPIO_MODE_EVT_RISING;
  GPIO_InitStruct.Pull = GPIO_NOPULL;
  HAL_GPIO_Init(GPIOA, &GPIO_InitStruct);

  /*Configure GPIO pin : ACP_RST_Pin */
  GPIO_InitStruct.Pin = ACP_RST_Pin;
  GPIO_InitStruct.Mode = GPIO_MODE_OUTPUT_PP;
  GPIO_InitStruct.Pull = GPIO_NOPULL;
  GPIO_InitStruct.Speed = GPIO_SPEED_LOW;
  HAL_GPIO_Init(ACP_RST_GPIO_Port, &GPIO_InitStruct);

  /*Configure GPIO pin : OTG_FS_OC_Pin */
  GPIO_InitStruct.Pin = OTG_FS_OC_Pin;
  GPIO_InitStruct.Mode = GPIO_MODE_EVT_RISING;
  GPIO_InitStruct.Pull = GPIO_NOPULL;
  HAL_GPIO_Init(OTG_FS_OC_GPIO_Port, &GPIO_InitStruct);

  /*Configure GPIO pin : BOOT1_Pin */
  GPIO_InitStruct.Pin = BOOT1_Pin;
  GPIO_InitStruct.Mode = GPIO_MODE_INPUT;
  GPIO_InitStruct.Pull = GPIO_NOPULL;
  HAL_GPIO_Init(BOOT1_GPIO_Port, &GPIO_InitStruct);

  /*Configure GPIO pins : OTG_FS_ID_Pin OTG_FS_DM_Pin OTG_FS_DP_Pin */
  GPIO_InitStruct.Pin = OTG_FS_ID_Pin|OTG_FS_DM_Pin|OTG_FS_DP_Pin;
  GPIO_InitStruct.Mode = GPIO_MODE_AF_PP;
  GPIO_InitStruct.Pull = GPIO_NOPULL;
  GPIO_InitStruct.Speed = GPIO_SPEED_LOW;
  GPIO_InitStruct.Alternate = GPIO_AF12_OTG_HS_FS;
  HAL_GPIO_Init(GPIOB, &GPIO_InitStruct);

  /*Configure GPIO pin : VBUS_FS_Pin */
  GPIO_InitStruct.Pin = VBUS_FS_Pin;
  GPIO_InitStruct.Mode = GPIO_MODE_INPUT;
  GPIO_InitStruct.Pull = GPIO_NOPULL;
  HAL_GPIO_Init(VBUS_FS_GPIO_Port, &GPIO_InitStruct);

  /*Configure GPIO pin : TE_Pin */
  GPIO_InitStruct.Pin = TE_Pin;
  GPIO_InitStruct.Mode = GPIO_MODE_INPUT;
  GPIO_InitStruct.Pull = GPIO_NOPULL;
  HAL_GPIO_Init(TE_GPIO_Port, &GPIO_InitStruct);

  /*Configure GPIO pins : RDX_Pin WRX_DCX_Pin */
  GPIO_InitStruct.Pin = RDX_Pin|WRX_DCX_Pin;
  GPIO_InitStruct.Mode = GPIO_MODE_OUTPUT_PP;
  GPIO_InitStruct.Pull = GPIO_NOPULL;
  GPIO_InitStruct.Speed = GPIO_SPEED_LOW;
  HAL_GPIO_Init(GPIOD, &GPIO_InitStruct);

  /*Configure GPIO pins : LD3_Pin LD4_Pin */
  GPIO_InitStruct.Pin = LD3_Pin|LD4_Pin;
  GPIO_InitStruct.Mode = GPIO_MODE_OUTPUT_PP;
  GPIO_InitStruct.Pull = GPIO_NOPULL;
  GPIO_InitStruct.Speed = GPIO_SPEED_LOW;
  HAL_GPIO_Init(GPIOG, &GPIO_InitStruct);

}

/* USER CODE BEGIN 4 */
#define BUFFER_NUM 2
#define SAMPLE_NUM 16 /*[TODO]Try larger sample number.*/
#define SAMPLE_MAX 2047
volatile uint32_t SignalBuffer[BUFFER_NUM][SAMPLE_NUM];

dsp mydsp;

int c = 0;
/* USER CODE END 4 */

/* SignalProcessTask function */
void SignalProcessTask(void const * argument)
{

  /* USER CODE BEGIN 5 */
	// ADC
	HAL_ADC_Start_DMA(&hadc1, SignalBuffer[0], SAMPLE_NUM);
	// DAC
	HAL_DAC_Start_DMA(&hdac, DAC_CHANNEL_2, SignalBuffer[1], SAMPLE_NUM, DAC_ALIGN_12B_R);
	// Timer
	HAL_TIM_Base_Start(&htim6);
	// **DSP**
	dsp_init(&mydsp,
			"uRock0.1",
			 "{}",
			1,
			SAMPLE_NUM);
	// **Bluetooth handler**
	bluetooth_handler_init();

  /* Infinite loop */
	for(;;)
	{
		dsp_execute(&mydsp,SignalBuffer[0],SignalBuffer[1]);

		/* Performance mointor */
		if(c > 3000){
			HAL_GPIO_TogglePin(GPIOG,GPIO_PIN_14);
			c = 0;
		}
		else
			c++;

	}
  /* USER CODE END 5 */
}

/************************ (C) COPYRIGHT STMicroelectronics *****END OF FILE****/
